# CTRL_MMR0_CTRL_MMR0_MMR_ID_09000000h register map
Vendor: Texas Instruments
Peripheral module from a debugger description file (folder am62L).
Registers are 32-bit, read-only, reset 0x0 unless marked. A register's access mark holds for its fields unless they carry their own. Offsets are as the file gives them; lines under a group give offsets from that group; [hi:lo] are bit positions; {n}, {i} and the like mark numbered series; 'fields as' and 'values as' point back to an identical list; <NAME> marks a mode.

## CTRL_MMR0_MMR_ID
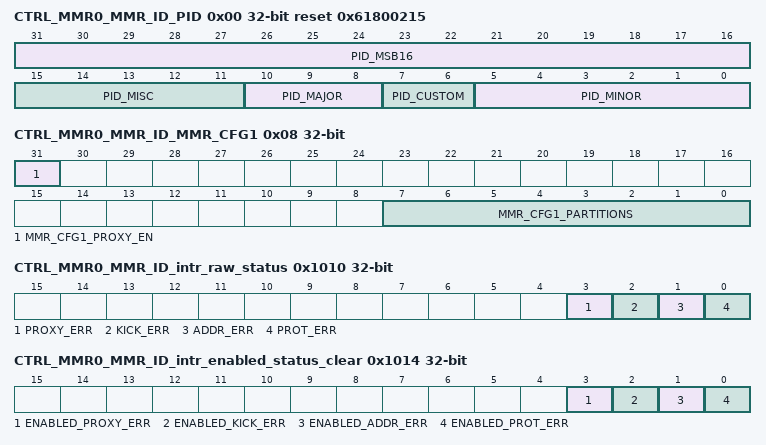
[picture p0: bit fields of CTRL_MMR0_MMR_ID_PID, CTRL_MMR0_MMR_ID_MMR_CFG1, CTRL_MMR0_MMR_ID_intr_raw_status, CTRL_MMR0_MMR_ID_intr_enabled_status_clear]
0x00 CTRL_MMR0_MMR_ID_PID reset 0x61800215
  [31:16] PID_MSB16 — Reset Source: mod_g_rst_n
  [15:11] PID_MISC — Reset Source: mod_g_rst_n
  [10:8] PID_MAJOR — Reset Source: mod_g_rst_n
  [7:6] PID_CUSTOM — Reset Source: mod_g_rst_n
  [5:0] PID_MINOR — Reset Source: mod_g_rst_n
0x08 CTRL_MMR0_MMR_ID_MMR_CFG1 — Indicates the MMR configuration
  [31] MMR_CFG1_PROXY_EN — Proxy addressing not supported Reset Source: mod_por_rst_n
  [7:0] MMR_CFG1_PARTITIONS — No Partitions Present Reset Source: mod_por_rst_n
0x1010 CTRL_MMR0_MMR_ID_intr_raw_status access not given
  [3] PROXY_ERR — Proxy0 access violation error. Raw status is read. Write a 1 to set the status. Writing a 0 has no effect. Reset Source: mod_g_rst_n (access R/W1TS)
  [2] KICK_ERR — Kick access violation error. Raw status is read. Write a 1 to set the status. Writing a 0 has no effect. Reset Source: mod_g_rst_n (access R/W1TS)
  [1] ADDR_ERR — Addressing violation error. Raw status is read. Write a 1 to set the status. Writing a 0 has no effect. Reset Source: mod_g_rst_n (access R/W1TS)
  [0] PROT_ERR — Protection violation error. Raw status is read. Write a 1 to set the status. Writing a 0 has no effect. Reset Source: mod_g_rst_n (access R/W1TS)
0x1014 CTRL_MMR0_MMR_ID_intr_enabled_status_clear access not given
  [3] ENABLED_PROXY_ERR — Proxy0 access violation error. Enabled status is read. Write a 1 to clear the status. Writing a 0 has no effect. Reset Source: mod_g_rst_n (access R/W1TC)
  [2] ENABLED_KICK_ERR — Kick access violation error. Enabled status is read. Write a 1 to clear the status. Writing a 0 has no effect. Reset Source: mod_g_rst_n (access R/W1TC)
  [1] ENABLED_ADDR_ERR — Addressing violation error. Enabled status is read. Write a 1 to clear the status. Writing a 0 has no effect. Reset Source: mod_g_rst_n (access R/W1TC)
  [0] ENABLED_PROT_ERR — Protection violation error. Enabled status is read. Write a 1 to clear the status. Writing a 0 has no effect. Reset Source: mod_g_rst_n (access R/W1TC)
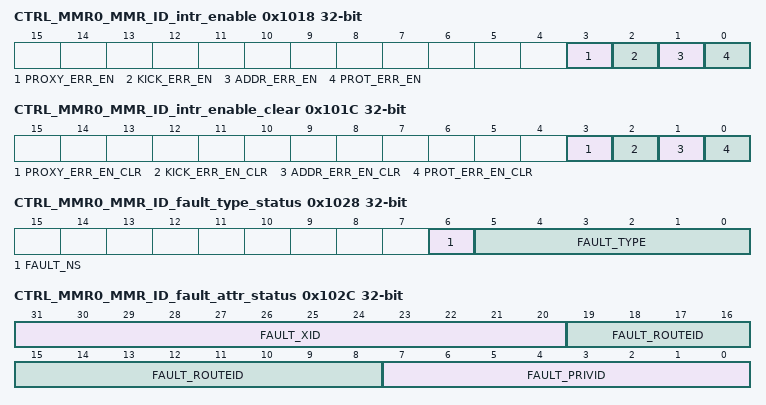
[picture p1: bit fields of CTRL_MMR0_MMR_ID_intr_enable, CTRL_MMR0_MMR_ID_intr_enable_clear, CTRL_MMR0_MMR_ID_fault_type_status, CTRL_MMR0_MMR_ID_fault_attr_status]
0x1018 CTRL_MMR0_MMR_ID_intr_enable access not given
  [3] PROXY_ERR_EN — Proxy0 access violation error enable. Write a 1 to set the enable. Writing a 0 has no effect. Reset Source: mod_g_rst_n (access R/W1TS)
  [2] KICK_ERR_EN — Kick access violation error enable. Write a 1 to set the enable. Writing a 0 has no effect. Reset Source: mod_g_rst_n (access R/W1TS)
  [1] ADDR_ERR_EN — Addressing violation error enable. Write a 1 to set the enable. Writing a 0 has no effect. Reset Source: mod_g_rst_n (access R/W1TS)
  [0] PROT_ERR_EN — Protection violation error enable. Write a 1 to set the enable. Writing a 0 has no effect. Reset Source: mod_g_rst_n (access R/W1TS)
0x101C CTRL_MMR0_MMR_ID_intr_enable_clear access not given
  [3] PROXY_ERR_EN_CLR — Proxy0 access violation error enable clear. Write a 1 to clear the enable. Writing a 0 has no effect. Reset Source: mod_g_rst_n (access R/W1TC)
  [2] KICK_ERR_EN_CLR — Kick access violation error enable clear. Write a 1 to clear the enable. Writing a 0 has no effect. Reset Source: mod_g_rst_n (access R/W1TC)
  [1] ADDR_ERR_EN_CLR — Addressing violation error enable clear. Write a 1 to clear the enable. Writing a 0 has no effect. Reset Source: mod_g_rst_n (access R/W1TC)
  [0] PROT_ERR_EN_CLR — Protection violation error enable clear. Write a 1 to clear the enable. Writing a 0 has no effect. Reset Source: mod_g_rst_n (access R/W1TC)
0x1020 CTRL_MMR0_MMR_ID_eoi rw
  [7:0] EOI_VECTOR — EOI vector value. Write this with interrupt distribution value in the chip. Reset Source: mod_g_rst_n
0x1024 CTRL_MMR0_MMR_ID_fault_address
  [31:0] FAULT_ADDR — Fault Address. Reset Source: mod_g_rst_n
0x1028 CTRL_MMR0_MMR_ID_fault_type_status
  [6] FAULT_NS — Non-secure access. Reset Source: mod_g_rst_n
  [5:0] FAULT_TYPE — Fault Type 10_0000 = Supervisor read fault - priv = 1 dir = 1 dtype != 1 01_0000 = Supervisor write fault - priv = 1 dir = 0 00_1000 = Supervisor execute fault - priv = 1 dir = 1 dtype = 1 00_0100 = User read fault - priv = 0 dir = 1 dtype = 1 00_0010 = User write fault - priv = 0 dir = 0 00_0001 = User execute fault - priv = 0 dir = 1 dtype = 1 00_0000 = No fault Reset Source: mod_g_rst_n
0x102C CTRL_MMR0_MMR_ID_fault_attr_status
  [31:20] FAULT_XID — XID. Reset Source: mod_g_rst_n
  [19:8] FAULT_ROUTEID — Route ID. Reset Source: mod_g_rst_n
  [7:0] FAULT_PRIVID — Privilege ID. Reset Source: mod_g_rst_n
0x1030 CTRL_MMR0_MMR_ID_fault_clear wo
  [0] FAULT_CLR — Fault clear. Writing a 1 clears the current fault. Writing a 0 has no effect. Reset Source: mod_g_rst_n
